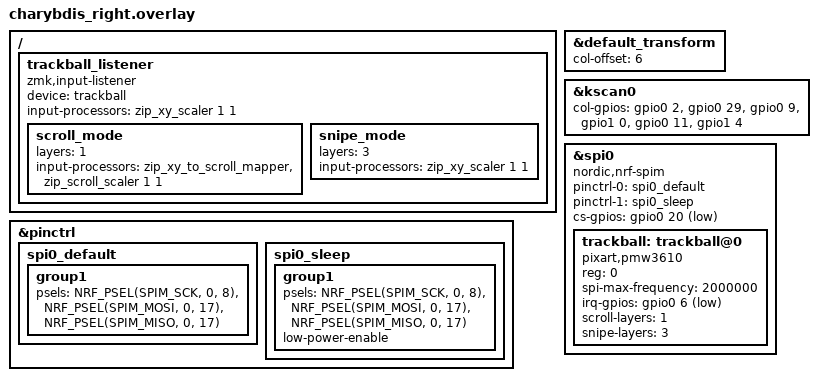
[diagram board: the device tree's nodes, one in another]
/*
 * Copyright (c) 2020 ZMK Contributors
 *
 * SPDX-License-Identifier: MIT
 */
 
#include "charybdis.dtsi"

&default_transform {
    col-offset = <6>;
}; 

&kscan0 {
	col-gpios
		= <&gpio0 2 (GPIO_ACTIVE_HIGH | GPIO_PULL_DOWN)>
		, <&gpio0 29 (GPIO_ACTIVE_HIGH | GPIO_PULL_DOWN)>
		, <&gpio0 9 (GPIO_ACTIVE_HIGH | GPIO_PULL_DOWN)>
		, <&gpio1 0  (GPIO_ACTIVE_HIGH | GPIO_PULL_DOWN)>
		, <&gpio0 11 (GPIO_ACTIVE_HIGH | GPIO_PULL_DOWN)>
		, <&gpio1 4  (GPIO_ACTIVE_HIGH | GPIO_PULL_DOWN)>
		;
};

// trackball bus
&pinctrl {
    spi0_default: spi0_default {
        group1 {
            psels = <NRF_PSEL(SPIM_SCK, 0, 8)>,
                <NRF_PSEL(SPIM_MOSI, 0, 17)>,
                <NRF_PSEL(SPIM_MISO, 0, 17)>;
        };
    };

    spi0_sleep: spi0_sleep {
        group1 {
            psels = <NRF_PSEL(SPIM_SCK, 0, 8)>,
                <NRF_PSEL(SPIM_MOSI, 0, 17)>,
                <NRF_PSEL(SPIM_MISO, 0, 17)>;
            low-power-enable;
        };
    };
};

&spi0 {
    status = "okay";
    compatible = "nordic,nrf-spim";
    pinctrl-0 = <&spi0_default>;
    pinctrl-1 = <&spi0_sleep>;
    pinctrl-names = "default", "sleep";
    cs-gpios = <&gpio0 20 GPIO_ACTIVE_LOW>;

    trackball: trackball@0 {
        status = "okay";
        compatible = "pixart,pmw3610";
        reg = <0>;
        spi-max-frequency = <2000000>;
        irq-gpios = <&gpio0 6 (GPIO_ACTIVE_LOW | GPIO_PULL_UP)>;
        scroll-layers = <1>;
        snipe-layers = <3>;
        //automouse-layer = <3>;

    };
};

//RGB bus


/ {
    trackball_listener {
        compatible = "zmk,input-listener";
        device = <&trackball>;

        // 기본 레이어 (BASE, FUNC, NUM) - 일반 속도
        // 듀얼 모니터: 1.25배 빠르게 (multiplier 5, divisor 4)
        // 커서가 가볍다면: 3 2(1.5x), 너무 빠르다면: 6 5(1.2x)
        input-processors = <&zip_xy_scaler 1 1>;

        // [스크롤 모드] _SCROLL 레이어가 켜진 동안만 XY→스크롤 + 1.25x
         scroll_mode {
           layers = <1>;
           input-processors = <&zip_xy_to_scroll_mapper
                               &zip_scroll_scaler 1 1>;
         };

        // 정밀 모드 (SNIPE 레이어) - 느린 속도
        // 종료 버튼 클릭 등 세밀한 작업용
        snipe_mode {
            layers = <3>;  // SNIPE 레이어
            input-processors = <&zip_xy_scaler 1 1>;  // 1x 속도
        };
    };
};


